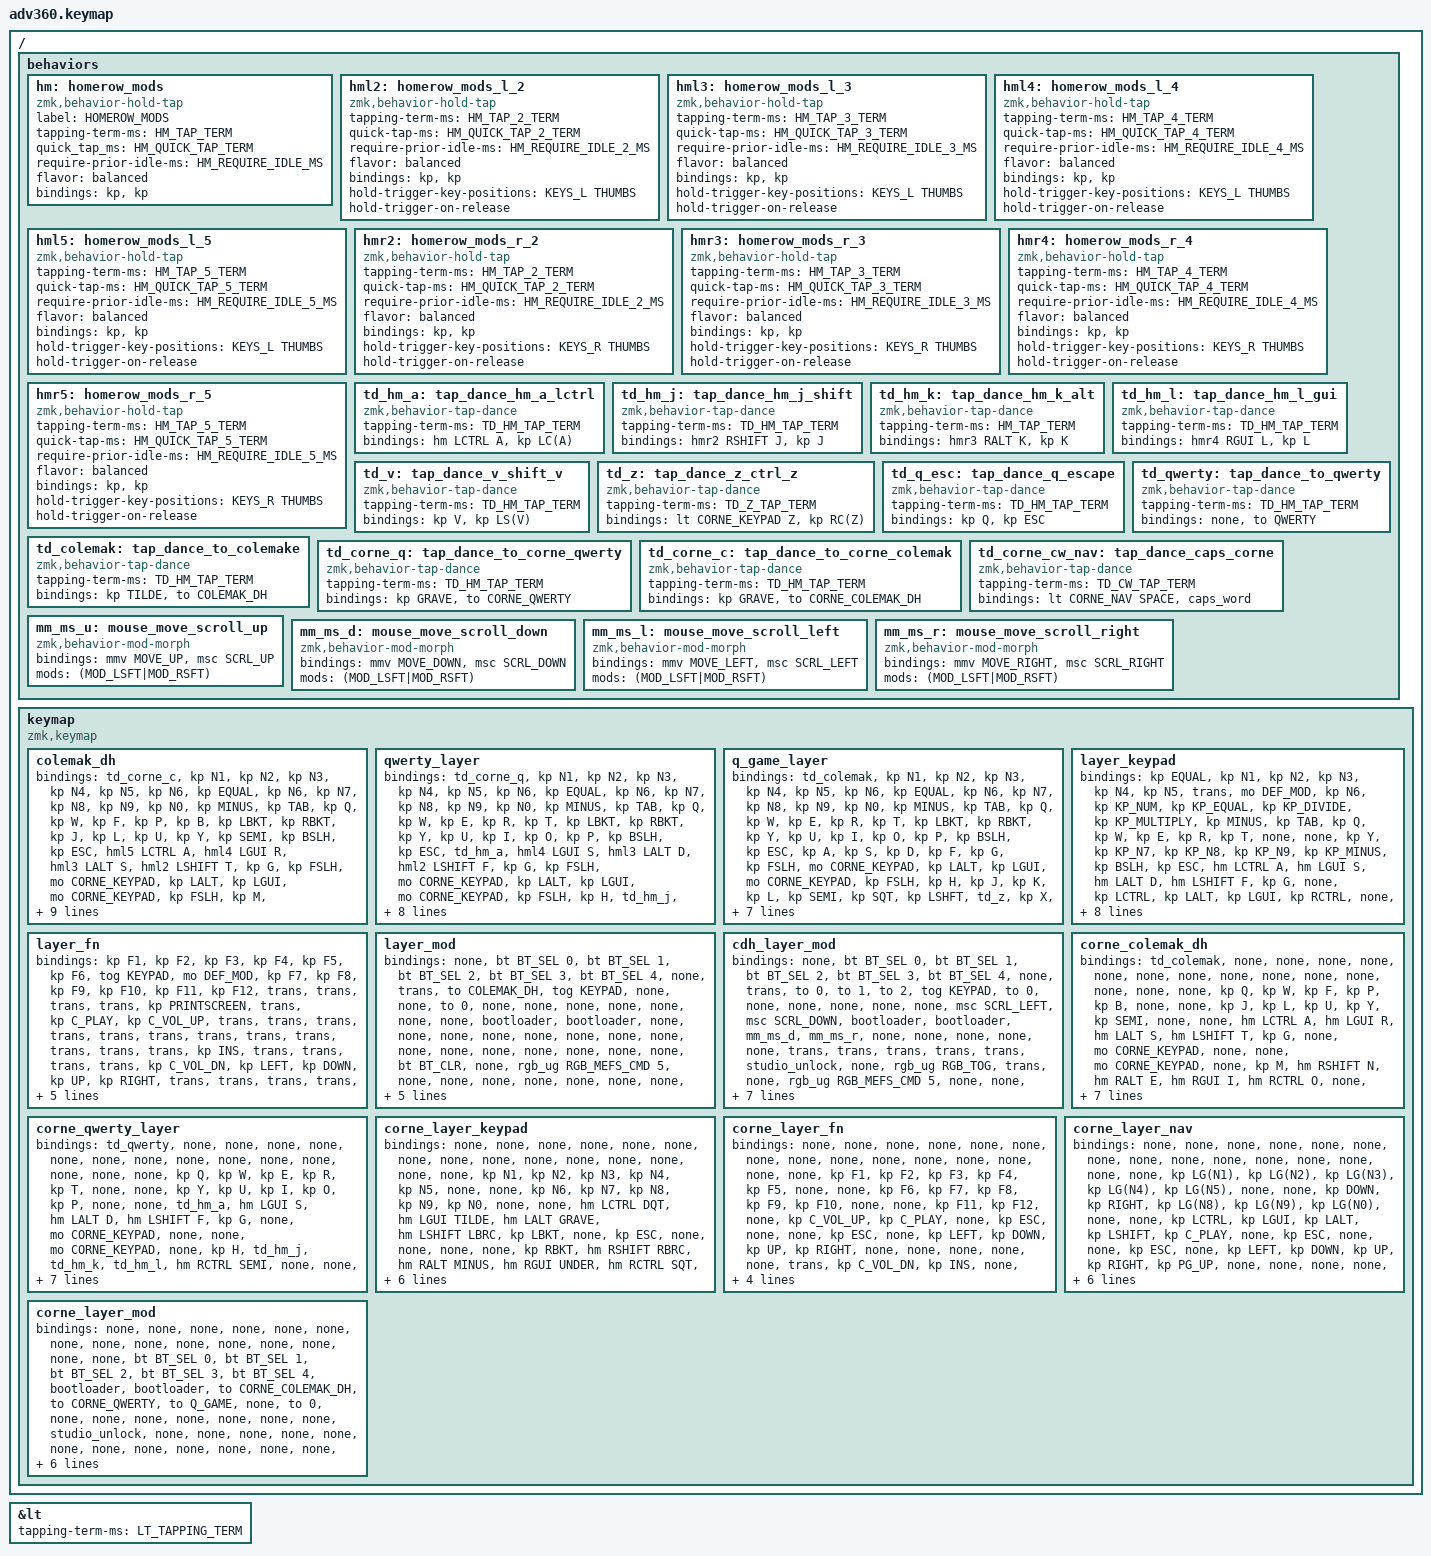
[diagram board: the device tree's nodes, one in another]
/*
 * Copyright (c) 2020 The ZMK Contributors
 *
 * SPDX-License-Identifier: MIT
 */
/* THIS FILE WAS GENERATED!
 *
 * This file was generated automatically. You may or may not want to
 * edit it directly.
 */

#include <behaviors.dtsi>
#include <dt-bindings/zmk/backlight.h>
#include <dt-bindings/zmk/bt.h>
#include <dt-bindings/zmk/keys.h>
#include <dt-bindings/zmk/rgb.h>
#include <dt-bindings/zmk/stp.h>
#include <dt-bindings/zmk/pointing.h>
#include "zmk-helpers/key-labels/adv360.h"

#define QWERTY             0
#define COLEMAK_DH         1
#define Q_GAME             2
#define KEYPAD             3
#define FUNCTION           4
#define DEF_MOD            5
#define CDH_MOD            6
#define CORNE_COLEMAK_DH   7
#define CORNE_QWERTY       8
#define CORNE_KEYPAD       9
#define CORNE_FUNCTION     10
#define CORNE_NAV          11
#define CORNE_DEF_MOD      12

#define TD_HM_TAP_TERM     175
#define TD_Z_TAP_TERM      250
#define HM_TAP_TERM          180
#define HM_TAP_2_TERM        190
#define HM_TAP_3_TERM        190
#define HM_TAP_4_TERM        200
#define HM_TAP_5_TERM        250
#define HM_QUICK_TAP_TERM    150
#define HM_QUICK_TAP_2_TERM  150
#define HM_QUICK_TAP_3_TERM  150
#define HM_QUICK_TAP_4_TERM  150
#define HM_QUICK_TAP_5_TERM  150
#define HM_REQUIRE_IDLE_MS   125
#define HM_REQUIRE_IDLE_2_MS 125
#define HM_REQUIRE_IDLE_3_MS 125
#define HM_REQUIRE_IDLE_4_MS 125
#define HM_REQUIRE_IDLE_5_MS 125
#define HM_REQUIRE_IDLE_MS 125
#define TD_CW_TAP_TERM     190
#define LT_TAPPING_TERM    100

#define KEYS_L LN0 LN1 LN2 LN3 LN4 LN5 \
               LT0 LT1 LT2 LT3 LT4 LT5 \
               LM0 LM1 LM2 LM3 LM4 LM5 \
               LB0 LB1 LB2 LB3 LB4 LB5  // Left-hand keys.

#define KEYS_R RN0 RN1 RN2 RN3 RN4 RN5 \
               RT0 RT1 RT2 RT3 RT4 RT5 \
               RM0 RM1 RM2 RM3 RM4 RM5 \
               RB0 RB1 RB2 RB3 RB4 RB5  // Right-hand keys.

#define THUMBS LH2 LH1 LH0 RH0 RH1 RH2  // Thumb keys.

&lt {
    tapping-term-ms = <LT_TAPPING_TERM>;
};

/ {
    behaviors {
        #include "macros.dtsi"
        #include "version.dtsi"

        hm: homerow_mods {
            compatible = "zmk,behavior-hold-tap";
            label = "HOMEROW_MODS";
            #binding-cells = <2>;
            tapping-term-ms = <HM_TAP_TERM>;
            quick_tap_ms = <HM_QUICK_TAP_TERM>;
            require-prior-idle-ms = <HM_REQUIRE_IDLE_MS>;
            flavor = "balanced";
            bindings = <&kp>, <&kp>;
        };

        hml2: homerow_mods_l_2 {
            compatible = "zmk,behavior-hold-tap";
            #binding-cells = <2>;
            tapping-term-ms = <HM_TAP_2_TERM>;
            quick-tap-ms = <HM_QUICK_TAP_2_TERM>;
            require-prior-idle-ms = <HM_REQUIRE_IDLE_2_MS>;
            flavor = "balanced";
            bindings = <&kp>, <&kp>;
            hold-trigger-key-positions = <KEYS_L THUMBS>;
            hold-trigger-on-release;
        };

        hml3: homerow_mods_l_3 {
            compatible = "zmk,behavior-hold-tap";
            #binding-cells = <2>;
            tapping-term-ms = <HM_TAP_3_TERM>;
            quick-tap-ms = <HM_QUICK_TAP_3_TERM>;
            require-prior-idle-ms = <HM_REQUIRE_IDLE_3_MS>;
            flavor = "balanced";
            bindings = <&kp>, <&kp>;
            hold-trigger-key-positions = <KEYS_L THUMBS>;
            hold-trigger-on-release;
        };

        hml4: homerow_mods_l_4 {
            compatible = "zmk,behavior-hold-tap";
            #binding-cells = <2>;
            tapping-term-ms = <HM_TAP_4_TERM>;
            quick-tap-ms = <HM_QUICK_TAP_4_TERM>;
            require-prior-idle-ms = <HM_REQUIRE_IDLE_4_MS>;
            flavor = "balanced";
            bindings = <&kp>, <&kp>;
            hold-trigger-key-positions = <KEYS_L THUMBS>;
            hold-trigger-on-release;
        };

        hml5: homerow_mods_l_5 {
            compatible = "zmk,behavior-hold-tap";
            #binding-cells = <2>;
            tapping-term-ms = <HM_TAP_5_TERM>;
            quick-tap-ms = <HM_QUICK_TAP_5_TERM>;
            require-prior-idle-ms = <HM_REQUIRE_IDLE_5_MS>;
            flavor = "balanced";
            bindings = <&kp>, <&kp>;
            hold-trigger-key-positions = <KEYS_L THUMBS>;
            hold-trigger-on-release;
        };

        hmr2: homerow_mods_r_2 {
            compatible = "zmk,behavior-hold-tap";
            #binding-cells = <2>;
            tapping-term-ms = <HM_TAP_2_TERM>;
            quick-tap-ms = <HM_QUICK_TAP_2_TERM>;
            require-prior-idle-ms = <HM_REQUIRE_IDLE_2_MS>;
            flavor = "balanced";
            bindings = <&kp>, <&kp>;
            hold-trigger-key-positions = <KEYS_R THUMBS>;
            hold-trigger-on-release;
        };

        hmr3: homerow_mods_r_3 {
            compatible = "zmk,behavior-hold-tap";
            #binding-cells = <2>;
            tapping-term-ms = <HM_TAP_3_TERM>;
            quick-tap-ms = <HM_QUICK_TAP_3_TERM>;
            require-prior-idle-ms = <HM_REQUIRE_IDLE_3_MS>;
            flavor = "balanced";
            bindings = <&kp>, <&kp>;
            hold-trigger-key-positions = <KEYS_R THUMBS>;
            hold-trigger-on-release;
        };

        hmr4: homerow_mods_r_4 {
            compatible = "zmk,behavior-hold-tap";
            #binding-cells = <2>;
            tapping-term-ms = <HM_TAP_4_TERM>;
            quick-tap-ms = <HM_QUICK_TAP_4_TERM>;
            require-prior-idle-ms = <HM_REQUIRE_IDLE_4_MS>;
            flavor = "balanced";
            bindings = <&kp>, <&kp>;
            hold-trigger-key-positions = <KEYS_R THUMBS>;
            hold-trigger-on-release;
        };

        hmr5: homerow_mods_r_5 {
            compatible = "zmk,behavior-hold-tap";
            #binding-cells = <2>;
            tapping-term-ms = <HM_TAP_5_TERM>;
            quick-tap-ms = <HM_QUICK_TAP_5_TERM>;
            require-prior-idle-ms = <HM_REQUIRE_IDLE_5_MS>;
            flavor = "balanced";
            bindings = <&kp>, <&kp>;
            hold-trigger-key-positions = <KEYS_R THUMBS>;
            hold-trigger-on-release;
        };

        td_hm_a: tap_dance_hm_a_lctrl {
            compatible = "zmk,behavior-tap-dance";
            #binding-cells = <0>;
            tapping-term-ms = <TD_HM_TAP_TERM>;
            bindings = <&hm LCTRL A>, <&kp LC(A)>;
        };

        td_hm_j: tap_dance_hm_j_shift {
            compatible = "zmk,behavior-tap-dance";
            #binding-cells = <0>;
            tapping-term-ms = <TD_HM_TAP_TERM>;
            bindings = <&hmr2 RSHIFT J>, <&kp J>;
        };

        td_hm_k: tap_dance_hm_k_alt {
            compatible = "zmk,behavior-tap-dance";
            #binding-cells = <0>;
            tapping-term-ms = <HM_TAP_TERM>;
            bindings = <&hmr3 RALT K>, <&kp K>;
        };

        td_hm_l: tap_dance_hm_l_gui {
            compatible = "zmk,behavior-tap-dance";
            #binding-cells = <0>;
            tapping-term-ms = <TD_HM_TAP_TERM>;
            bindings = <&hmr4 RGUI L>, <&kp L>;
        };

        td_v: tap_dance_v_shift_v {
            compatible = "zmk,behavior-tap-dance";
            #binding-cells = <0>;
            tapping-term-ms = <TD_HM_TAP_TERM>;
            bindings = <&kp V>, <&kp LS(V)>;
        };

        td_z: tap_dance_z_ctrl_z {
            compatible = "zmk,behavior-tap-dance";
            #binding-cells = <0>;
            tapping-term-ms = <TD_Z_TAP_TERM>;
            bindings = <&lt CORNE_KEYPAD Z>, <&kp RC(Z)>;
        };

        td_q_esc: tap_dance_q_escape {
            compatible = "zmk,behavior-tap-dance";
            #binding-cells = <0>;
            tapping-term-ms = <TD_HM_TAP_TERM>;
            bindings = <&kp Q>, <&kp ESC>;
        };

        td_qwerty: tap_dance_to_qwerty {
            compatible = "zmk,behavior-tap-dance";
            #binding-cells = <0>;
            tapping-term-ms = <TD_HM_TAP_TERM>;
            bindings = <&none>, <&to QWERTY>;
        };

        td_colemak: tap_dance_to_colemake {
            compatible = "zmk,behavior-tap-dance";
            #binding-cells = <0>;
            tapping-term-ms = <TD_HM_TAP_TERM>;
            bindings = <&kp TILDE>, <&to COLEMAK_DH>;
        };

        td_corne_q: tap_dance_to_corne_qwerty {
            compatible = "zmk,behavior-tap-dance";
            #binding-cells = <0>;
            tapping-term-ms = <TD_HM_TAP_TERM>;
            bindings = <&kp GRAVE>, <&to CORNE_QWERTY>;
        };

        td_corne_c: tap_dance_to_corne_colemak {
            compatible = "zmk,behavior-tap-dance";
            #binding-cells = <0>;
            tapping-term-ms = <TD_HM_TAP_TERM>;
            bindings = <&kp GRAVE>, <&to CORNE_COLEMAK_DH>;
        };

        td_corne_cw_nav: tap_dance_caps_corne {
            compatible = "zmk,behavior-tap-dance";
            #binding-cells = <0>;
            tapping-term-ms = <TD_CW_TAP_TERM>;
            bindings = <&lt CORNE_NAV SPACE>, <&caps_word>;
        };
        mm_ms_u: mouse_move_scroll_up {
            compatible = "zmk,behavior-mod-morph";
            #binding-cells = <0>;
            bindings = <&mmv MOVE_UP>, <&msc SCRL_UP>;
            mods = <(MOD_LSFT|MOD_RSFT)>;
        };
        mm_ms_d: mouse_move_scroll_down {
            compatible = "zmk,behavior-mod-morph";
            #binding-cells = <0>;
            bindings = <&mmv MOVE_DOWN>, <&msc SCRL_DOWN>;
            mods = <(MOD_LSFT|MOD_RSFT)>;
        };
        mm_ms_l: mouse_move_scroll_left {
            compatible = "zmk,behavior-mod-morph";
            #binding-cells = <0>;
            bindings = <&mmv MOVE_LEFT>, <&msc SCRL_LEFT>;
            mods = <(MOD_LSFT|MOD_RSFT)>;
        };
        mm_ms_r: mouse_move_scroll_right {
            compatible = "zmk,behavior-mod-morph"; #binding-cells = <0>; bindings = <&mmv MOVE_RIGHT>, <&msc SCRL_RIGHT>; mods = <(MOD_LSFT|MOD_RSFT)>;
        };
    };

    keymap {
        compatible = "zmk,keymap";

        colemak_dh {
            bindings = <
&td_corne_c   &kp N1         &kp N2        &kp N3        &kp N4          &kp N5  &kp N6                                                                         &kp EQUAL     &kp N6  &kp N7          &kp N8        &kp  N9       &kp N0         &kp MINUS
&kp TAB       &kp Q          &kp W         &kp F         &kp P           &kp B   &kp LBKT                                                                       &kp RBKT      &kp J   &kp L           &kp U         &kp  Y        &kp SEMI       &kp BSLH
&kp ESC       &hml5 LCTRL A  &hml4 LGUI R  &hml3 LALT S  &hml2 LSHIFT T  &kp G   &kp FSLH  &mo CORNE_KEYPAD      &kp LALT      &kp LGUI   &mo CORNE_KEYPAD      &kp FSLH      &kp M   &hmr2 RSHIFT N  &hmr3 RALT E  &hmr4 RGUI I  &hmr5 RCTRL O  &kp SQT
&kp LSHFT     &td_z          &kp X         &kp C         &kp D           &kp V                                   &kp HOME      &kp PG_UP                                      &kp K   &kp H           &kp COMMA     &kp DOT       &kp FSLH       &kp RSHFT
&mo FUNCTION  &mo CDH_MOD    &kp CAPS      &kp LEFT      &kp RIGHT               &kp BSPC  &td_corne_cw_nav      &kp END       &kp PG_DN  &lt CORNE_NAV ENTER   &kp SPACE             &kp DOWN        &kp UP        &tog KEYPAD   &mo CDH_MOD    &mo FUNCTION
            >;
        };

        qwerty_layer {
            bindings = <
&td_corne_q   &kp N1        &kp N2        &kp N3        &kp N4          &kp N5  &kp N6                                                                         &kp EQUAL     &kp N6    &kp N7     &kp N8     &kp  N9       &kp N0            &kp MINUS
&kp TAB       &kp Q         &kp W         &kp E         &kp R           &kp T   &kp LBKT                                                                       &kp RBKT      &kp Y     &kp U      &kp I      &kp  O        &kp P             &kp BSLH
&kp ESC       &td_hm_a      &hml4 LGUI S  &hml3 LALT D  &hml2 LSHIFT  F &kp G   &kp FSLH  &mo CORNE_KEYPAD      &kp LALT      &kp LGUI   &mo CORNE_KEYPAD      &kp FSLH      &kp H     &td_hm_j   &td_hm_k   &td_hm_l      &hml5 RCTRL SEMI  &kp SQT
&kp LSHFT     &td_z         &kp X         &kp C         &td_v           &kp B                                   &kp HOME      &kp PG_UP                                      &kp N     &kp M      &kp COMMA  &kp DOT       &kp FSLH          &kp RSHFT
&mo FUNCTION  &mo DEF_MOD   &none         &kp LEFT      &kp RIGHT               &kp BSPC  &td_corne_cw_nav      &kp END       &kp PG_DN  &lt CORNE_NAV ENTER   &kp SPACE               &kp DOWN   &kp UP     &tog KEYPAD   &mo DEF_MOD       &mo FUNCTION
            >;
        };

        q_game_layer {
            bindings = <
&td_colemak   &kp N1        &kp N2        &kp N3      &kp N4        &kp N5  &kp N6                                                                         &kp EQUAL     &kp N6    &kp N7     &kp N8     &kp  N9       &kp N0          &kp MINUS
&kp TAB       &kp Q         &kp W         &kp E       &kp R         &kp T   &kp LBKT                                                                       &kp RBKT      &kp Y     &kp U      &kp I      &kp  O        &kp P           &kp BSLH
&kp ESC       &kp A         &kp S         &kp D       &kp F         &kp G   &kp FSLH  &mo CORNE_KEYPAD      &kp LALT      &kp LGUI   &mo CORNE_KEYPAD      &kp FSLH      &kp H     &kp J      &kp K      &kp  L        &kp SEMI        &kp SQT
&kp LSHFT     &td_z         &kp X         &kp C       &td_v         &kp B                                   &kp HOME      &kp PG_UP                                      &kp N     &kp M      &kp COMMA  &kp DOT       &kp FSLH        &kp RSHFT
&kp LCTRL     &mo DEF_MOD   &kp CORNE_NAV &kp LEFT    &kp RIGHT             &kp BSPC  &kp SPACE             &kp END       &kp PG_DN  &lt CORNE_NAV ENTER   &kp SPACE               &kp DOWN   &kp UP     &mo FUNCTION  &mo DEF_MOD     &kp RCTRL
            >;
        };

        layer_keypad {
            bindings = <
&kp EQUAL     &kp N1       &kp N2      &kp N3      &kp N4        &kp N5  &trans                                                   &mo DEF_MOD   &kp N6  &kp KP_NUM  &kp KP_EQUAL  &kp KP_DIVIDE  &kp KP_MULTIPLY  &kp MINUS
&kp TAB       &kp Q        &kp W       &kp E       &kp R         &kp T   &none                                                    &none         &kp Y   &kp KP_N7   &kp KP_N8     &kp KP_N9      &kp KP_MINUS     &kp BSLH
&kp ESC       &hm LCTRL A  &hm LGUI S  &hm LALT D  &hm LSHIFT F  &kp G   &none     &kp LCTRL  &kp LALT      &kp LGUI   &kp RCTRL  &none         &kp H   &kp KP_N4   &kp KP_N5     &kp KP_N6      &kp KP_PLUS      &kp SQT
&kp LSHFT     &kp Z        &kp X       &kp C       &kp V         &kp B                        &kp HOME      &kp PG_UP                           &kp N   &kp KP_N1   &kp KP_N2     &kp KP_N3      &kp KP_ENTER     &kp RSHFT
&mo FUNCTION  &trans       &kp CAPS    &kp LEFT    &kp RIGHT             &kp BSPC  &kp DEL    &kp END       &kp PG_DN  &kp ENTER  &kp KP_N0             &kp UP      &kp DOWN      &kp KP_DOT     &kp RBKT         &mo FUNCTION
            >;
        };

        layer_fn {
        bindings = <
&kp F1  &kp F2  &kp F3  &kp F4  &kp F5           &kp F6  &tog KEYPAD                                        &mo DEF_MOD   &kp F7    &kp F8     &kp F9     &kp F10    &kp F11  &kp F12
&trans  &trans  &trans  &trans  &kp PRINTSCREEN  &trans  &kp C_PLAY                                         &kp C_VOL_UP  &trans    &trans     &trans     &trans     &trans   &trans
&trans  &trans  &trans  &trans  &trans           &trans  &kp INS      &trans   &trans      &trans  &trans   &kp C_VOL_DN  &kp LEFT  &kp DOWN   &kp UP     &kp RIGHT  &trans   &trans
&trans  &trans  &trans  &trans  &trans           &trans                        &trans      &trans                         &kp HOME  &kp PG_DN  &kp PG_UP  &kp END    &trans   &trans
&trans  &trans  &trans  &trans  &trans                   &kp DEL      &kp ESC  &trans      &trans  &kp ESC  &kp TAB                  &trans     &trans    &trans     &trans   &trans
            >;
        };

        layer_mod {
            bindings = <
&none  &bt BT_SEL 0  &bt BT_SEL 1  &bt BT_SEL 2  &bt BT_SEL 3  &bt BT_SEL 4  &none                                                  &trans                  &to COLEMAK_DH   &tog KEYPAD       &none       &none  &to 0  &none
&none  &none         &none         &none         &none         &none         &bootloader                                            &bootloader             &none            &none             &none       &none  &none  &none
&none  &none         &none         &none         &none         &none         &none        &none  &none      &bt BT_CLR  &none       &rgb_ug RGB_MEFS_CMD 5  &none            &none             &none       &none  &none  &none
&none  &none         &none         &none         &none         &none                             &none      &none                                           &none            &none             &none       &none  &none  &none
&none  &none         &none         &none         &none                       &none        &none  &none      &none       &bl BL_TOG  &rgb_ug RGB_TOG                          &bl BL_INC        &bl BL_DEC  &none  &none  &none
            >;
        };

        cdh_layer_mod {
            bindings = <
&none  &bt BT_SEL 0  &bt BT_SEL 1  &bt BT_SEL 2  &bt BT_SEL 3     &bt BT_SEL 4    &none                                                                  &trans                  &to 0    &to 1       &to 2       &tog KEYPAD   &to 0  &none
&none  &none         &none         &none         &msc SCRL_LEFT   &msc SCRL_DOWN  &bootloader                                                            &bootloader             &mm_ms_d &mm_ms_r    &none       &none         &none  &none
&none  &trans        &trans        &trans        &trans           &trans          &studio_unlock  &none  &rgb_ug RGB_TOG    &trans          &none        &rgb_ug RGB_MEFS_CMD 5  &none    &none       &none       &none         &none  &none
&none  &none         &none         &none         &msc SCRL_RIGHT  &msc SCRL_UP                           &msc SCRL_RIGHT    &msc SCRL_UP                                         &mm_ms_u &mm_ms_l    &none       &none         &none  &none
&none  &none         &none         &none         &none                            &none           &none  &msc SCRL_LEFT     &msc SCRL_DOWN  &mkp LCLK    &mkp RCLK                        &bl BL_INC  &bl BL_DEC  &none         &none  &none
            >;
        };

        corne_colemak_dh {
            bindings = <
&td_colemak  &none              &none                &none                 &none         &none  &none                                                                &none      &none   &none         &none           &none         &none           &none
&none        &kp Q              &kp W                &kp F                 &kp P         &kp B  &none                                                                &none      &kp J   &kp L         &kp U           &kp Y         &kp SEMI        &none
&none        &hm LCTRL A        &hm LGUI R           &hm LALT S            &hm LSHIFT T  &kp G  &none     &mo CORNE_KEYPAD      &none   &none  &mo CORNE_KEYPAD      &none      &kp M   &hm RSHIFT N  &hm RALT E      &hm RGUI I    &hm RCTRL O     &none
&none        &td_z              &kp X                &kp C                 &kp D         &kp V                                  &none   &none                                   &kp K   &hm RSHIFT H  &hm RALT COMMA  &hm RGUI DOT  &hm RCTRL FSLH  &none
&none        &mo CORNE_DEF_MOD  &none                &none                 &none                &kp BSPC  &td_corne_cw_nav      &none   &none  &lt CORNE_NAV ENTER   &kp SPACE          &none         &none           &none         &none           &none
            >;
        };

        corne_qwerty_layer {
            bindings = <
&td_qwerty  &none               &none                &none                 &none         &none  &none                                                                &none      &none  &none     &none                     &none                  &none                  &none
&none       &kp Q               &kp W                &kp E                 &kp R         &kp T  &none                                                                &none      &kp Y  &kp U     &kp I                     &kp  O                 &kp P                  &none
&none       &td_hm_a            &hm LGUI S           &hm LALT D            &hm LSHIFT F  &kp G  &none     &mo CORNE_KEYPAD      &none   &none  &mo CORNE_KEYPAD      &none      &kp H  &td_hm_j  &td_hm_k                  &td_hm_l               &hm RCTRL SEMI         &none
&none       &td_z               &kp X                &kp C                 &td_v         &kp B                                  &none   &none                                   &kp N  &kp M     &lt CORNE_NAV COMMA  &lt CORNE_DEF_MOD DOT  &lt CORNE_KEYPAD FSLH  &none
&none       &mo CORNE_DEF_MOD   &none                &none                 &none                &kp BSPC  &td_corne_cw_nav      &none   &none  &lt CORNE_NAV ENTER   &kp SPACE         &none     &none                     &none                  &mo CORNE_DEF_MOD      &none
            >;
        };

        corne_layer_keypad {
            bindings = <
&none  &none            &none           &none           &none             &none      &none                                               &none      &none     &none            &none           &none           &none          &none
&none  &kp N1           &kp N2          &kp N3          &kp N4            &kp N5     &none                                               &none      &kp N6    &kp N7           &kp N8          &kp N9          &kp N0         &none
&none  &hm LCTRL DQT    &hm LGUI TILDE  &hm LALT GRAVE  &hm LSHIFT LBRC   &kp LBKT   &none    &kp ESC     &none   &none  &none           &none      &kp RBKT  &hm RSHIFT RBRC  &hm RALT MINUS  &hm RGUI UNDER  &hm RCTRL SQT  &none
&none  &trans           &kp X           &none           &kp PIPE          &kp BSLH                        &none   &none                             &kp FSLH  &kp EQUAL        &kp COMMA       &kp DOT         &trans         &none
&none  &none            &none           &none           &none                        &kp DEL  &kp LSHIFT  &none   &none  &hm RSHIFT ESC  &kp TAB              &none            &none           &none           &none          &none
            >;
        };

        corne_layer_fn {
        bindings = <
&none   &none    &none    &none   &none         &none       &none                                              &none     &none     &none      &none    &none      &none    &none
&none   &kp F1   &kp F2   &kp F3  &kp F4        &kp F5      &none                                              &none     &kp F6    &kp F7     &kp F8   &kp F9     &kp F10  &none
&none   &kp F11  &kp F12  &none   &kp C_VOL_UP  &kp C_PLAY  &none     &kp ESC     &none   &none    &kp ESC     &none     &kp LEFT  &kp DOWN   &kp UP   &kp RIGHT  &none    &none
&none   &none    &none    &trans  &kp C_VOL_DN  &kp INS                           &none   &none                          &kp HOME  &kp PG_DN  &kp PG_UP  &kp END  &none    &none
&none   &none    &none    &none   &none                     &kp DEL   &kp LSHIFT  &none   &kp ESC  &kp ENTER   &kp TAB             &none      &none      &none    &none    &none
            >;
        };

        corne_layer_nav {
        bindings = <
&none   &none       &none       &none         &none         &none       &none                                              &none    &none     &none      &none       &none       &none       &none
&none   &kp LG(N1)  &kp LG(N2)  &kp LG(N3)    &kp LG(N4)    &kp LG(N5)  &none                                              &none    &kp DOWN  &kp RIGHT  &kp LG(N8)  &kp LG(N9)  &kp LG(N0)  &none
&none   &kp LCTRL   &kp LGUI    &kp LALT      &kp LSHIFT    &kp C_PLAY  &none      &kp ESC    &none   &none    &kp ESC     &none    &kp LEFT  &kp DOWN   &kp UP      &kp RIGHT   &kp PG_UP   &none
&none   &none       &none       &kp C_VOL_DN  &kp C_VOL_UP  &kp INS                           &none   &none                         &kp UP    &kp LEFT   &kp HOME    &kp END     &kp PG_DN   &none
&none   &none       &none       &none         &none                     &kp DEL   &kp LSHIFT  &none   &kp ESC  &kp ENTER   &kp TAB            &none      &none       &none       &none       &none
            >;
        };

        corne_layer_mod {
            bindings = <
&none  &none         &none         &none         &none         &none         &none                                     &none        &none                 &none             &none                   &none       &none       &none
&none  &bt BT_SEL 0  &bt BT_SEL 1  &bt BT_SEL 2  &bt BT_SEL 3  &bt BT_SEL 4  &bootloader                               &bootloader  &to CORNE_COLEMAK_DH  &to CORNE_QWERTY  &to Q_GAME              &none       &to 0       &none
&none  &none         &none         &none         &none         &none         &studio_unlock      &none   &none  &none  &none        &none                 &none             &none                   &none       &none       &none       &none
&none  &none         &none         &trans        &none         &none                             &none   &none  &none               &bt BT_CLR            &none             &rgb_ug RGB_MEFS_CMD 5  &none       &none       &none
&none  &none         &none         &none         &none                       &none        &none  &none   &none  &none  &none                              &bl BL_TOG        &rgb_ug RGB_TOG         &bl BL_INC  &bl BL_DEC  &none
            >;
        };

    };
};
